VERSION "23"

NS_ :

BS_:

BU_:

BO_ 320 ICU_HaltMessage: 1 Vector__XXX
 SG_ io_state : 0|8@1+ (1,0) [0|0] "" Vector__XXX

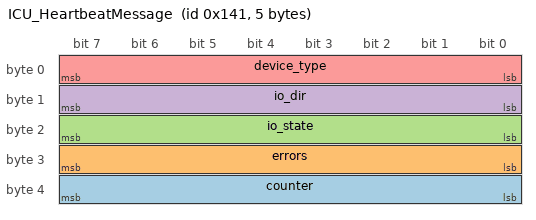
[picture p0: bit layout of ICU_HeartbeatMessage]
BO_ 321 ICU_HeartbeatMessage: 5 Vector__XXX
 SG_ counter : 32|8@1+ (1,0) [0|0] "" Vector__XXX
 SG_ errors : 24|8@1+ (1,0) [0|0] "" Vector__XXX
 SG_ io_state : 16|8@1+ (1,0) [0|0] "" Vector__XXX
 SG_ io_dir : 8|8@1+ (1,0) [0|0] "" Vector__XXX
 SG_ device_type : 0|8@1+ (1,0) [0|0] "" Vector__XXX

BO_ 322 ICU_IoStateMessage: 1 Vector__XXX
 SG_ io_state : 0|8@1+ (1,0) [0|0] "" Vector__XXX

BO_ 323 ICU_SetIoStateMessage: 1 Vector__XXX
 SG_ io_state : 0|8@1+ (1,0) [0|0] "" Vector__XXX

BO_ 324 ICU_SetParameterMessage: 5 Vector__XXX
 SG_ value : 8|32@1- (1,0) [0|0] "" Vector__XXX
 SG_ param_id : 0|8@1+ (1,0) [0|0] "" Vector__XXX

BO_ 325 ICU_GetParameterMessage: 1 Vector__XXX
 SG_ param_id : 0|8@1+ (1,0) [0|0] "" Vector__XXX
